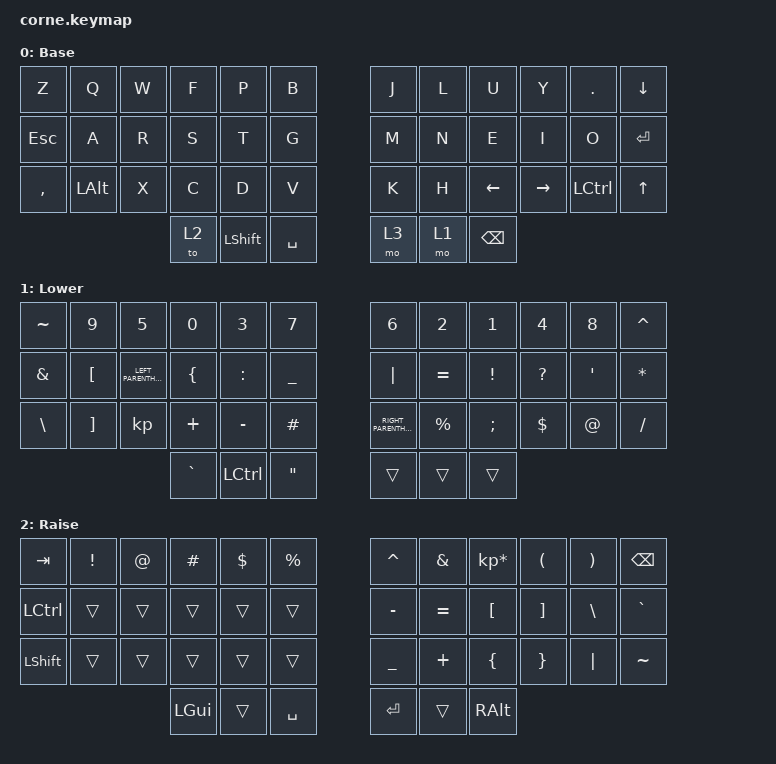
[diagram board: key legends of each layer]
/*
 /*
 * Copyright (c) 2020 The ZMK Contributors
 *
 * SPDX-License-Identifier: MIT
 */

#include <behaviors.dtsi>
#include <dt-bindings/zmk/keys.h>
#include <dt-bindings/zmk/bt.h>

/ {
        keymap {
                compatible = "zmk,keymap";

                default_layer {
                        display-name = "Base";
                        bindings = <
   &kp Z     &kp Q        &kp W &kp F        &kp P          &kp B         &kp J   &kp L  &kp U     &kp Y     &kp DOT          &kp DOWN
   &kp ESC   &kp A        &kp R &kp S        &kp T          &kp G         &kp M   &kp N  &kp E     &kp I     &kp O            &kp ENTER
   &kp COMMA &kp LEFT_ALT &kp X &kp C        &kp D          &kp V         &kp K   &kp H  &kp LEFT  &kp RIGHT &kp LEFT_CONTROL &kp UP
                                &to 2        &kp LEFT_SHIFT &kp SPACE     &mo 3   &mo 1  &kp BACKSPACE
                        >;
                };

                lower_layer {
                        display-name = "Lower";
                        bindings = <
   &kp TILDE     &kp N9            &kp N5               &kp N0         &kp N3       &kp N7                            &kp N6                &kp N2      &kp N1          &kp N4       &kp N8           &kp CARET
   &kp AMPERSAND &kp LEFT_BRACKET  &kp LEFT_PARENTHESES &kp LEFT_BRACE &kp COLON    &kp UNDERSCORE                    &kp PIPE              &kp EQUAL   &kp EXCLAMATION &kp QUESTION &kp SINGLE_QUOTE &kp ASTERISK
   &kp BACKSLASH &kp RIGHT_BRACKET &kp                  &kp PLUS       &kp MINUS    &kp HASH                          &kp RIGHT_PARENTHESES &kp PERCENT &kp SEMICOLON   &kp DOLLAR   &kp AT           &kp SLASH
                          	        &kp GRAVE     &kp LEFT_CONTROL       &kp DOUBLE_QUOTES                                              &trans  &trans    &trans
                        >;
                };

                raise_layer {
                        display-name = "Raise";
                        bindings = <
   &kp  TAB  &kp EXCL &kp AT &kp HASH &kp DLLR &kp PRCNT   &kp CARET &kp AMPS  &kp KP_MULTIPLY &kp LPAR &kp RPAR &kp BSPC
   &kp LCTRL &trans   &trans &trans   &trans   &trans      &kp MINUS &kp EQUAL &kp LBKT        &kp RBKT &kp BSLH &kp GRAVE
   &kp LSHFT &trans   &trans &trans   &trans   &trans      &kp UNDER &kp PLUS  &kp LBRC        &kp RBRC &kp PIPE &kp TILDE
                    	     &kp LGUI &trans   &kp SPACE   &kp RET   &trans    &kp RALT
                        >;
                };

                extra_1 {
                        status = "reserved";
                };

                extra_2 {
                        status = "reserved";
                };

                extra_3 {
                        status = "reserved";
                };
        };
}
